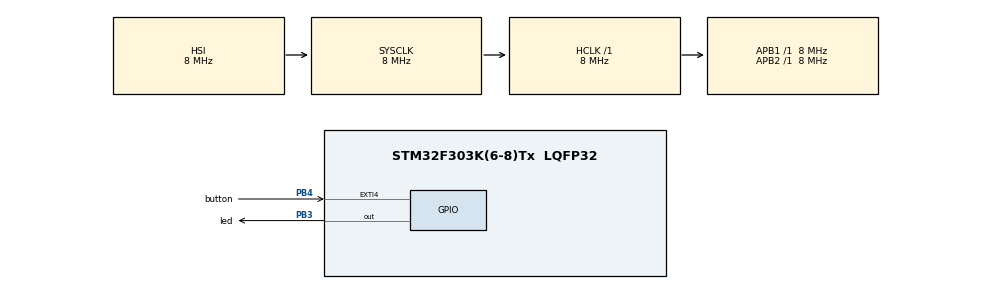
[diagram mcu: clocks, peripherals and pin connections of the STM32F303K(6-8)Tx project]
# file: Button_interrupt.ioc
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Mcu.Family=STM32F3
Mcu.Name=STM32F303K(6-8)Tx
Mcu.Package=LQFP32
NVIC.EXTI4_IRQn=true\:0\:0\:false\:false\:true\:true\:true
NVIC.PriorityGroup=NVIC_PRIORITYGROUP_4
NVIC.TIM1_TRG_COM_TIM17_IRQn=true\:0\:0\:false\:false\:true\:true\:true
PB3.GPIO_Label=led
PB3.Signal=GPIO_Output
PB4.GPIO_Label=button
PB4.GPIO_PuPd=GPIO_PULLDOWN
PB4.Signal=GPXTI4
ProjectManager.HeapSize=0x200
ProjectManager.StackSize=0x400
ProjectManager.TargetToolchain=TrueSTUDIO
RCC.AHBFreq_Value=8000000
RCC.APB1Freq_Value=8000000
RCC.APB2Freq_Value=8000000
RCC.CortexFreq_Value=8000000
RCC.HSE_VALUE=8000000
RCC.HSI_VALUE=8000000
RCC.SYSCLKFreq_VALUE=8000000
TIM17.Period=100
TIM17.Prescaler=800
VP_TIM17_VS_ClockSourceINT.Mode=Enable_Timer
board=custom

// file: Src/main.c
/* USER CODE BEGIN Header */
/**
  ******************************************************************************
  * @file           : main.c
  * @brief          : Main program body
  ******************************************************************************
  * @attention
  *
  * <h2><center>&copy; Copyright (c) 2019 STMicroelectronics.
  * All rights reserved.</center></h2>
  *
  * This software component is licensed by ST under BSD 3-Clause license,
  * the "License"; You may not use this file except in compliance with the
  * License. You may obtain a copy of the License at:
  *                        opensource.org/licenses/BSD-3-Clause
  *
  ******************************************************************************
  */
/* USER CODE END Header */

#include "main.h"

TIM_HandleTypeDef htim17;

void SystemClock_Config(void);
static void MX_GPIO_Init(void);
static void MX_TIM17_Init(void);

/* USER CODE BEGIN 0 */
uint8_t lock_button = 0;
/* USER CODE END 0 */

int main(void)
{

  /* MCU Configuration--------------------------------------------------------*/

  /* Reset of all peripherals, Initializes the Flash interface and the Systick. */
  HAL_Init();

  /* Configure the system clock */
  SystemClock_Config();

  /* Initialize all configured peripherals */
  MX_GPIO_Init();
  MX_TIM17_Init();

  /* Infinite loop */
  while (1)
  {

  }
}

void SystemClock_Config(void)
{
  RCC_OscInitTypeDef RCC_OscInitStruct = {0};
  RCC_ClkInitTypeDef RCC_ClkInitStruct = {0};

  /** Initializes the CPU, AHB and APB busses clocks
  */
  RCC_OscInitStruct.OscillatorType = RCC_OSCILLATORTYPE_HSI;
  RCC_OscInitStruct.HSIState = RCC_HSI_ON;
  RCC_OscInitStruct.HSICalibrationValue = RCC_HSICALIBRATION_DEFAULT;
  RCC_OscInitStruct.PLL.PLLState = RCC_PLL_NONE;
  if (HAL_RCC_OscConfig(&RCC_OscInitStruct) != HAL_OK)
  {
    Error_Handler();
  }
  /** Initializes the CPU, AHB and APB busses clocks
  */
  RCC_ClkInitStruct.ClockType = RCC_CLOCKTYPE_HCLK|RCC_CLOCKTYPE_SYSCLK
                              |RCC_CLOCKTYPE_PCLK1|RCC_CLOCKTYPE_PCLK2;
  RCC_ClkInitStruct.SYSCLKSource = RCC_SYSCLKSOURCE_HSI;
  RCC_ClkInitStruct.AHBCLKDivider = RCC_SYSCLK_DIV1;
  RCC_ClkInitStruct.APB1CLKDivider = RCC_HCLK_DIV1;
  RCC_ClkInitStruct.APB2CLKDivider = RCC_HCLK_DIV1;

  if (HAL_RCC_ClockConfig(&RCC_ClkInitStruct, FLASH_LATENCY_0) != HAL_OK)
  {
    Error_Handler();
  }
}

static void MX_TIM17_Init(void)
{

  htim17.Instance = TIM17;
  htim17.Init.Prescaler = 800;
  htim17.Init.CounterMode = TIM_COUNTERMODE_UP;
  htim17.Init.Period = 100;
  htim17.Init.ClockDivision = TIM_CLOCKDIVISION_DIV1;
  htim17.Init.RepetitionCounter = 0;
  htim17.Init.AutoReloadPreload = TIM_AUTORELOAD_PRELOAD_DISABLE;
  if (HAL_TIM_Base_Init(&htim17) != HAL_OK)
  {
    Error_Handler();
  }

}

static void MX_GPIO_Init(void)
{
  GPIO_InitTypeDef GPIO_InitStruct = {0};

  /* GPIO Ports Clock Enable */
  __HAL_RCC_GPIOB_CLK_ENABLE();

  /*Configure GPIO pin Output Level */
  HAL_GPIO_WritePin(led_GPIO_Port, led_Pin, GPIO_PIN_RESET);

  /*Configure GPIO pin : led_Pin */
  GPIO_InitStruct.Pin = led_Pin;
  GPIO_InitStruct.Mode = GPIO_MODE_OUTPUT_PP;
  GPIO_InitStruct.Pull = GPIO_NOPULL;
  GPIO_InitStruct.Speed = GPIO_SPEED_FREQ_LOW;
  HAL_GPIO_Init(led_GPIO_Port, &GPIO_InitStruct);

  /*Configure GPIO pin : button_Pin */
  GPIO_InitStruct.Pin = button_Pin;
  GPIO_InitStruct.Mode = GPIO_MODE_IT_RISING;
  GPIO_InitStruct.Pull = GPIO_PULLDOWN;
  HAL_GPIO_Init(button_GPIO_Port, &GPIO_InitStruct);

  /* EXTI interrupt init*/
  HAL_NVIC_SetPriority(EXTI4_IRQn, 0, 0);
  HAL_NVIC_EnableIRQ(EXTI4_IRQn);

}

/* USER CODE BEGIN 4 */
// interrupções de GPIO
void HAL_GPIO_EXTI_Callback(uint16_t GPIO_Pin)
{
	if(GPIO_Pin==button_Pin && !lock_button)
	{
		// fazer o debouncer para o botao
		lock_button=1;

		__HAL_TIM_CLEAR_IT(&htim17, TIM_IT_UPDATE);// limpar o timer 17
		HAL_TIM_Base_Start_IT(&htim17);// inciar o timer 17
	}
	else
		__NOP();
}

// interrupção de timer
void HAL_TIM_PeriodElapsedCallback(TIM_HandleTypeDef *htim)
{
	if(htim->Instance==TIM17)
	{
		HAL_TIM_Base_Stop_IT(&htim17);// parar de contar o timer
		lock_button=0;

		HAL_GPIO_TogglePin(GPIOB, led_Pin);// inverter o estado do led
	}
	else
		__NOP();
}
/* USER CODE END 4 */

void Error_Handler(void)
{
}

/************************ (C) COPYRIGHT STMicroelectronics *****END OF FILE****/
